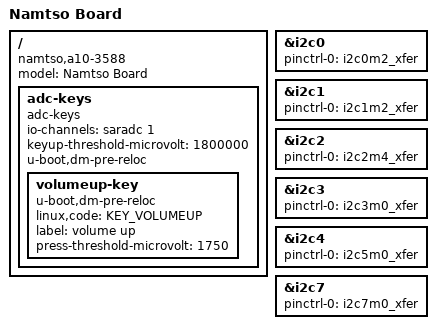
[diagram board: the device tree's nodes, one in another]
// SPDX-License-Identifier: (GPL-2.0+ OR MIT)
/*
 * Copyright (c) 2023 Namtso Electronics Co., Ltd
 *
 */

/dts-v1/;
#include "rk3588.dtsi"
#include "rk3588-u-boot.dtsi"
#include <dt-bindings/input/input.h>

/ {
	model = "Namtso Board";
	compatible = "namtso,a10-3588", "rockchip,rk3588";

	adc-keys {
		compatible = "adc-keys";
		io-channels = <&saradc 1>;
		io-channel-names = "buttons";
		keyup-threshold-microvolt = <1800000>;
		u-boot,dm-pre-reloc;
		status = "okay";

		volumeup-key {
			u-boot,dm-pre-reloc;
			linux,code = <KEY_VOLUMEUP>;
			label = "volume up";
			press-threshold-microvolt = <1750>;
		};
	};
};

&i2c0 {
	status = "okay";
	pinctrl-names = "default";
	pinctrl-0 = <&i2c0m2_xfer>;
};

&i2c1 {
	status = "okay";
	pinctrl-names = "default";
	pinctrl-0 = <&i2c1m2_xfer>;
};

&i2c2 {
	pinctrl-names = "default";
	pinctrl-0 = <&i2c2m4_xfer>;
	status = "okay";
};

&i2c3 {
	status = "okay";
	pinctrl-names = "default";
	pinctrl-0 = <&i2c3m0_xfer>;
};

&i2c4 {
	pinctrl-names = "default";
	pinctrl-0 = <&i2c5m0_xfer>;
	status = "okay";
};

&i2c7 {
	pinctrl-names = "default";
	pinctrl-0 = <&i2c7m0_xfer>;
	status = "okay";
};
